# GD32A71x register map
File version: 1.0
CPU: CM7 r2p1, little endian, MPU, FPU, DSP, 4 interrupt priority bits
Registers are 32-bit, read-write, reset 0x0 unless marked. A register's access mark holds for its fields unless they carry their own. Offsets are from the block's base; [hi:lo] are bit positions; {n}, {i} and the like mark numbered series; 'fields as' and 'values as' point back to an identical list.

## IRM — Interrupt requests management
Base 0x40023800
0x00 CTL — Control register
  [0] MOEN — Monitor enable
0x04 IRN wo reset 0xFF — Interrupt response number register
  [7:0] IRQN — The number for interrupt response from the interrupt service routine
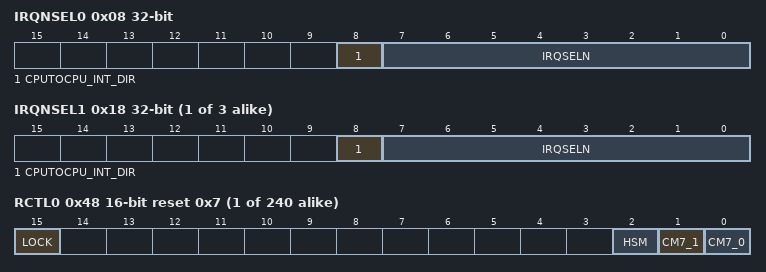
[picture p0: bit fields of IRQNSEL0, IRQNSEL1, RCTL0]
0x08 IRQNSEL0 — Interrupt request number select register 0
  [8] CPUTOCPU_INT_DIR — The selected IRQ21~IRQ24 interrupt direction to monitor
  [7:0] IRQSELN — The selected interrupt request number to monitor
0x0C CKTH0 — Clock threshold register 0
  [23:0] MCT — The maximum clock threshold from request to interrupt response for the selected monitored interrupt
0x10 CKCNT0 — Clock counter register 0
  [23:0] CLKCNT — IRM clock cycle counter
0x14 CMPO0 ro — Comparison output register
  [0] CMPOR — Comparison between the set interrupt response threshold of IRM_CKTH and the counter value of IRM_CKCNT
{0x8+0x10*i} IRQNSEL{i} (i=1..3) — Interrupt request number select register {i}
  [8] CPUTOCPU_INT_DIR — The selected IRQ21~IRQ24 interrupt direction to monitor
  [7:0] IRQSELN — the selected interrupt request number to monitor
0x1C CKTH1 — Clock threshold register
  [23:0] MCT — the maximum clock threshold from request to interrupt response for the selected monitored interrupt
{0x10+0x10*i} CKCNT{i} (i=1..3) — Clock counter register
  [23:0] CLKCNT — irm clock cycle counter
{0x14+0x10*i} CMPO{i} ro (i=1..3) — Comparison output register {i}
  fields as CMPO0
0x2C CKTH2 — Clock threshold register 2
  fields as CKTH1
0x3C CKTH3 — Clock threshold register
  fields as CKTH1
{0x48+2i} RCTL{i} 16-bit reset 0x7 (i=0..239) — Routing control register {i}
  [15] LOCK — Lock the routing of the corresponding interrupt request
  [2] HSM — HSM Cortex-M23 core Interrupt routing enable
  [1] CM7_1 — Cortex-M7_1 core interrupt routing enable
  [0] CM7_0 — Cortex-M7_0 core interrupt routing enable

## JDC — Debug system JDC
Base 0x4000EC00
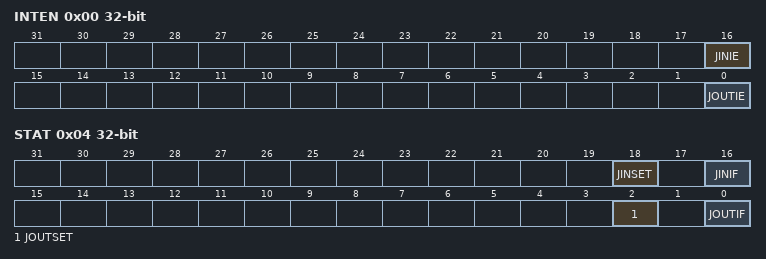
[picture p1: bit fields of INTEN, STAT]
0x00 INTEN — Interrupt enable register
  [16] JINIE — JIN interrupt enable
  [0] JOUTIE — JOUT interrupt enable
0x04 STAT access per field — Status register
  [18] JINSET ro
  [16] JINIF rw — The new data is written to the JDC_JIN_APB_DATA register interrupt flag
  [2] JOUTSET ro
  [0] JOUTIF rw — The JOUTSET bit is cleared by tool reading JDC_JOUT_DATA register interrupt flag
0x08 JOUT_APB_DATA
  [31:0] JOUT_APB_DATA — The JDC_JOUT_APB_DATA register stores data that has been written via APB
0x0C JIN_APB_DATA ro
  [31:0] JIN_APB_DATA — The JDC_JIN_APB_DATA register contains data written to the JTAG input data register (JDC_JIN_DATA) through the JTAG port

## MTC — Memory test controller
Base 0x40024400
0x00 CTL0 — Control register 0
  [15:0] GMTEN — Global memory test enable
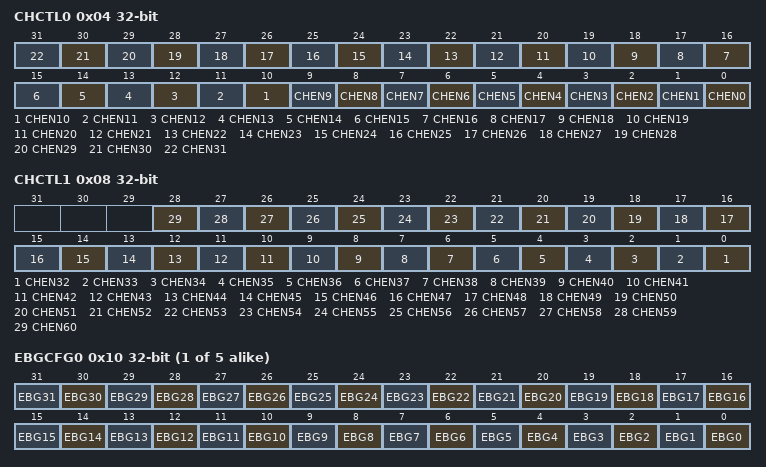
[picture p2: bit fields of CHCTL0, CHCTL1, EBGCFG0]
0x04 CHCTL0 — Channel control register 0
  [n] CHEN{n} (n=0..31) — Memory test channel enable bit {n}
0x08 CHCTL1 — Channel control register 1
  [n-32] CHEN{n} (n=32..60) — Memory test channel enable bit {n}
0x0C CTL1 — Control register 1
  [1:0] EDCMOD — EDC error bits generation mode selection
{0x10+4i} EBGCFG{i} (i=0..4) — Error bits generate configuration register {i}
  [n] EBG{n} (n=0..31) — Error bits generate configuration bit {n}
0x24 TMREN — MTC Triple Modular Redundancy enable register
  [0] MTC_TMR_EN — MTC TMR enable bit
0x28 TMRSTAT ro — MTC Triple Modular Redundancy Status register
  [0] MTC_TMR_ERR — MTC TMR error flag bit
0x2C TMRFC — MTC Triple Modular Redundancy Flag Clear register
  [0] MTC_TMR_FC — Clear MTC TMR error flag

## PRPU — Peripheral register protection unit
Base 0x40038000
{0x0+4i} LKPROT{i} (i=0..104) — Lock protection register {i}
  [31:0] LKPROT_KEY — Lock peripheral register protection key bits
